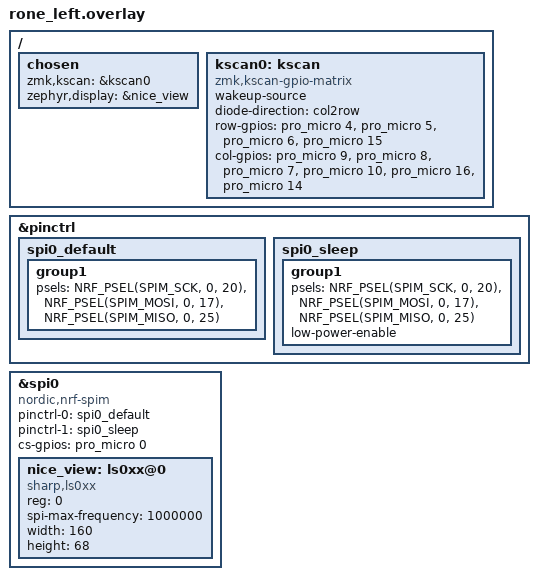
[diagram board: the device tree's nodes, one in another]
#include "rone.dtsi"

/ {
    chosen {
        zmk,kscan = &kscan0;
    };

    kscan0: kscan {
        compatible = "zmk,kscan-gpio-matrix";
        wakeup-source;
        diode-direction = "col2row";

        row-gpios
            = <&pro_micro  4 (GPIO_PULL_DOWN | GPIO_ACTIVE_HIGH)>
            , <&pro_micro  5 (GPIO_PULL_DOWN | GPIO_ACTIVE_HIGH)>
            , <&pro_micro  6 (GPIO_PULL_DOWN | GPIO_ACTIVE_HIGH)>
            , <&pro_micro 15 (GPIO_PULL_DOWN | GPIO_ACTIVE_HIGH)>
            ;

        col-gpios
            = <&pro_micro  9 GPIO_ACTIVE_HIGH>
            , <&pro_micro  8 GPIO_ACTIVE_HIGH>
            , <&pro_micro  7 GPIO_ACTIVE_HIGH>
            , <&pro_micro 10 GPIO_ACTIVE_HIGH>
            , <&pro_micro 16 GPIO_ACTIVE_HIGH>
            , <&pro_micro 14 GPIO_ACTIVE_HIGH>
            ;
    };
};

/* nice!view (Sharp memory LCD) on SPI.
 * Reuses your existing wiring: SCK on the SCL pad (P0.20),
 * MOSI on the SDA pad (P0.17), CS on pro_micro pin 0. */
&pinctrl {
    spi0_default: spi0_default {
        group1 {
            psels = <NRF_PSEL(SPIM_SCK, 0, 20)>,
                    <NRF_PSEL(SPIM_MOSI, 0, 17)>,
                    <NRF_PSEL(SPIM_MISO, 0, 25)>;
        };
    };
    spi0_sleep: spi0_sleep {
        group1 {
            psels = <NRF_PSEL(SPIM_SCK, 0, 20)>,
                    <NRF_PSEL(SPIM_MOSI, 0, 17)>,
                    <NRF_PSEL(SPIM_MISO, 0, 25)>;
            low-power-enable;
        };
    };
};

&spi0 {
    status = "okay";
    compatible = "nordic,nrf-spim";
    pinctrl-0 = <&spi0_default>;
    pinctrl-1 = <&spi0_sleep>;
    pinctrl-names = "default", "sleep";
    cs-gpios = <&pro_micro 0 GPIO_ACTIVE_HIGH>;

    nice_view: ls0xx@0 {
        compatible = "sharp,ls0xx";
        reg = <0>;
        spi-max-frequency = <1000000>;
        width = <160>;
        height = <68>;
    };
};

/ {
    chosen {
        zephyr,display = &nice_view;
    };
};
